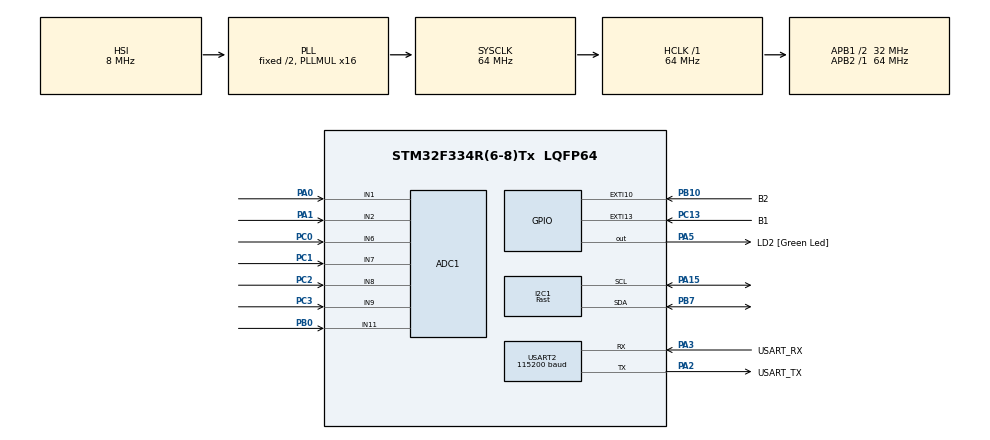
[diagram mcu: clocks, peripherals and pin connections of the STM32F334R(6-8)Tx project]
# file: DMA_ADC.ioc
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ADC1.Channel-0\#ChannelRegularConversion=ADC_CHANNEL_1
ADC1.Channel-1\#ChannelRegularConversion=ADC_CHANNEL_2
ADC1.Channel-2\#ChannelRegularConversion=ADC_CHANNEL_6
ADC1.Channel-3\#ChannelRegularConversion=ADC_CHANNEL_7
ADC1.Channel-4\#ChannelRegularConversion=ADC_CHANNEL_8
ADC1.Channel-5\#ChannelRegularConversion=ADC_CHANNEL_9
ADC1.Channel-6\#ChannelRegularConversion=ADC_CHANNEL_11
ADC1.ContinuousConvMode=ENABLE
ADC1.NbrOfConversion=7
ADC1.NbrOfConversionFlag=1
ADC1.Offset-0\#ChannelRegularConversion=0
ADC1.Offset-1\#ChannelRegularConversion=0
ADC1.Offset-2\#ChannelRegularConversion=0
ADC1.Offset-3\#ChannelRegularConversion=0
ADC1.Offset-4\#ChannelRegularConversion=0
ADC1.Offset-5\#ChannelRegularConversion=0
ADC1.Offset-6\#ChannelRegularConversion=0
ADC1.OffsetNumber-0\#ChannelRegularConversion=ADC_OFFSET_NONE
ADC1.OffsetNumber-1\#ChannelRegularConversion=ADC_OFFSET_NONE
ADC1.OffsetNumber-2\#ChannelRegularConversion=ADC_OFFSET_NONE
ADC1.OffsetNumber-3\#ChannelRegularConversion=ADC_OFFSET_NONE
ADC1.OffsetNumber-4\#ChannelRegularConversion=ADC_OFFSET_NONE
ADC1.OffsetNumber-5\#ChannelRegularConversion=ADC_OFFSET_NONE
ADC1.OffsetNumber-6\#ChannelRegularConversion=ADC_OFFSET_NONE
ADC1.Rank-0\#ChannelRegularConversion=1
ADC1.Rank-1\#ChannelRegularConversion=2
ADC1.Rank-2\#ChannelRegularConversion=3
ADC1.Rank-3\#ChannelRegularConversion=4
ADC1.Rank-4\#ChannelRegularConversion=5
ADC1.Rank-5\#ChannelRegularConversion=6
ADC1.Rank-6\#ChannelRegularConversion=7
ADC1.SamplingTime-0\#ChannelRegularConversion=ADC_SAMPLETIME_19CYCLES_5
ADC1.SamplingTime-1\#ChannelRegularConversion=ADC_SAMPLETIME_19CYCLES_5
ADC1.SamplingTime-2\#ChannelRegularConversion=ADC_SAMPLETIME_19CYCLES_5
ADC1.SamplingTime-3\#ChannelRegularConversion=ADC_SAMPLETIME_19CYCLES_5
ADC1.SamplingTime-4\#ChannelRegularConversion=ADC_SAMPLETIME_19CYCLES_5
ADC1.SamplingTime-5\#ChannelRegularConversion=ADC_SAMPLETIME_19CYCLES_5
ADC1.SamplingTime-6\#ChannelRegularConversion=ADC_SAMPLETIME_19CYCLES_5
ADC1.SamplingTimeOPAMP-6\#ChannelRegularConversion=ADC_SAMPLETIME_61CYCLES_5
ADC1.SubFamily=STM32F334x8
ADC1.master=1
Dma.ADC1.0.Direction=DMA_PERIPH_TO_MEMORY
Dma.ADC1.0.Instance=DMA1_Channel1
Dma.ADC1.0.MemDataAlignment=DMA_MDATAALIGN_WORD
Dma.ADC1.0.MemInc=DMA_MINC_ENABLE
Dma.ADC1.0.Mode=DMA_CIRCULAR
Dma.ADC1.0.PeriphDataAlignment=DMA_PDATAALIGN_WORD
Dma.ADC1.0.PeriphInc=DMA_PINC_DISABLE
Dma.ADC1.0.Priority=DMA_PRIORITY_LOW
Dma.Request0=ADC1
I2C1.I2C_Speed_Mode=I2C_Fast
I2C1.Timing=0x0000020B
Mcu.Family=STM32F3
Mcu.Name=STM32F334R(6-8)Tx
Mcu.Package=LQFP64
NVIC.DMA1_Channel1_IRQn=true\:0\:0\:false\:false\:true\:false\:true\:true
NVIC.EXTI15_10_IRQn=true\:0\:0\:false\:false\:true\:true\:true\:true
NVIC.PriorityGroup=NVIC_PRIORITYGROUP_0
NVIC.TIM2_IRQn=true\:0\:0\:false\:false\:true\:true\:true\:true
NVIC.TIM6_DAC1_IRQn=true\:0\:0\:false\:false\:true\:true\:true\:true
PA0.Mode=IN1-Single-Ended
PA0.Signal=ADC1_IN1
PA1.Mode=IN2-Single-Ended
PA1.Signal=ADC1_IN2
PA13.GPIO_Label=TMS
PA13.Mode=Serial_Wire
PA13.Signal=SYS_JTMS-SWDIO
PA14.GPIO_Label=TCK
PA14.Mode=Serial_Wire
PA14.Signal=SYS_JTCK-SWCLK
PA15.GPIO_Pu=GPIO_NOPULL
PA15.Mode=I2C
PA15.Signal=I2C1_SCL
PA2.GPIO_Label=USART_TX
PA2.Mode=Asynchronous
PA2.Signal=USART2_TX
PA3.GPIO_Label=USART_RX
PA3.Mode=Asynchronous
PA3.Signal=USART2_RX
PA5.GPIO_Label=LD2 [Green Led]
PA5.Signal=GPIO_Output
PB0.Mode=IN11-Single-Ended
PB0.Signal=ADC1_IN11
PB10.GPIO_Label=B2
PB10.GPIO_ModeDefaultEXTI=GPIO_MODE_IT_FALLING
PB10.Signal=GPXTI10
PB3.GPIO_Label=SWO
PB3.Signal=SYS_JTDO-TRACESWO
PB7.Mode=I2C
PB7.Signal=I2C1_SDA
PC0.Signal=ADCx_IN6
PC1.Signal=ADCx_IN7
PC13.GPIO_Label=B1
PC13.GPIO_ModeDefaultEXTI=GPIO_MODE_IT_FALLING
PC13.Signal=GPXTI13
PC14\ /\ OSC32_IN.Mode=LSE-External-Oscillator
PC14\ /\ OSC32_IN.Signal=RCC_OSC32_IN
PC15\ /\ OSC32_OUT.GPIO_Label=RCC_OSC32_OUT
PC15\ /\ OSC32_OUT.Mode=LSE-External-Oscillator
PC15\ /\ OSC32_OUT.Signal=RCC_OSC32_OUT
PC2.Signal=ADCx_IN8
PC3.Signal=ADCx_IN9
PF0\ /\ OSC_IN.Mode=HSE-External-Clock-Source
PF0\ /\ OSC_IN.Signal=RCC_OSC_IN
PF1\ /\ OSC_OUT.Signal=RCC_OSC_OUT
ProjectManager.HeapSize=0x200
ProjectManager.StackSize=0x400
ProjectManager.TargetToolchain=STM32CubeIDE
RCC.AHBFreq_Value=64000000
RCC.APB1CLKDivider=RCC_HCLK_DIV2
RCC.APB1Freq_Value=32000000
RCC.APB1TimFreq_Value=64000000
RCC.APB2Freq_Value=64000000
RCC.APB2TimFreq_Value=64000000
RCC.CortexFreq_Value=64000000
RCC.FLatency-AdvancedSettings=FLASH_LATENCY_2
RCC.HCLKFreq_Value=64000000
RCC.HSE_VALUE=8000000
RCC.HSI_VALUE=8000000
RCC.PLLMUL=RCC_PLL_MUL16
RCC.SYSCLKFreq_VALUE=64000000
RCC.SYSCLKSourceVirtual=RCC_SYSCLKSOURCE_PLLCLK
SH.ADCx_IN6.0=ADC1_IN6,IN6-Single-Ended
SH.ADCx_IN7.0=ADC1_IN7,IN7-Single-Ended
SH.ADCx_IN8.0=ADC1_IN8,IN8-Single-Ended
SH.ADCx_IN9.0=ADC1_IN9,IN9-Single-Ended
TIM2.Prescaler=72-1
TIM6.Period=10000
TIM6.Prescaler=7200-1
USART2.BaudRate=115200
USART2.VirtualMode-Asynchronous=VM_ASYNC
VP_TIM2_VS_ClockSourceINT.Mode=Internal
VP_TIM6_VS_ClockSourceINT.Mode=Enable_Timer
board=NUCLEO-F334R8

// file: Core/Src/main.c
/* USER CODE BEGIN Header */
/**
  ******************************************************************************
  * @file           : main.c
  * @brief          : Main program body
  ******************************************************************************
  * @attention
  *
  * Copyright (c) 2022 STMicroelectronics.
  * All rights reserved.
  *
  * This software is licensed under terms that can be found in the LICENSE file
  * in the root directory of this software component.
  * If no LICENSE file comes with this software, it is provided AS-IS.
  *
  ******************************************************************************
  */
/* USER CODE END Header */
#include "main.h"
#include "adc.h"
#include "dma.h"
#include "i2c.h"
#include "tim.h"
#include "usart.h"
#include "gpio.h"

/* USER CODE BEGIN Includes */
	#include "globalVars.h"
	#include "lcd_i2c.h"
/* USER CODE END Includes */

void SystemClock_Config(void);

int main(void)
{

  /* MCU Configuration--------------------------------------------------------*/

  /* Reset of all peripherals, Initializes the Flash interface and the Systick. */
  HAL_Init();

  /* Configure the system clock */
  SystemClock_Config();

  /* Initialize all configured peripherals */
  MX_GPIO_Init();
  MX_DMA_Init();
  MX_USART2_UART_Init();
  MX_ADC1_Init();
  MX_TIM2_Init();
  MX_TIM6_Init();
  MX_I2C1_Init();
  /* USER CODE BEGIN 2 */

	  HAL_TIM_Base_Start(&htim2); 	 // Start timer2 w trybie normalnym
	  HAL_TIM_Base_Start_IT(&htim6); // Start timera6 w trybie przerwania
	  disp.addr = (0x27 << 1);		 // Adres LCD'ka po I2C
	  disp.bl = true;				 // Włącz podświetlenie
	  lcd_init(&disp);				 // Inicjalizuj LCD

  /* USER CODE END 2 */

  /* Infinite loop */
  while (1)
  {

  }
}

void SystemClock_Config(void)
{
  RCC_OscInitTypeDef RCC_OscInitStruct = {0};
  RCC_ClkInitTypeDef RCC_ClkInitStruct = {0};
  RCC_PeriphCLKInitTypeDef PeriphClkInit = {0};

  /** Initializes the RCC Oscillators according to the specified parameters
  * in the RCC_OscInitTypeDef structure.
  */
  RCC_OscInitStruct.OscillatorType = RCC_OSCILLATORTYPE_HSI;
  RCC_OscInitStruct.HSIState = RCC_HSI_ON;
  RCC_OscInitStruct.HSICalibrationValue = RCC_HSICALIBRATION_DEFAULT;
  RCC_OscInitStruct.PLL.PLLState = RCC_PLL_ON;
  RCC_OscInitStruct.PLL.PLLSource = RCC_PLLSOURCE_HSI;
  RCC_OscInitStruct.PLL.PLLMUL = RCC_PLL_MUL16;
  if (HAL_RCC_OscConfig(&RCC_OscInitStruct) != HAL_OK)
  {
    Error_Handler();
  }

  /** Initializes the CPU, AHB and APB buses clocks
  */
  RCC_ClkInitStruct.ClockType = RCC_CLOCKTYPE_HCLK|RCC_CLOCKTYPE_SYSCLK
                              |RCC_CLOCKTYPE_PCLK1|RCC_CLOCKTYPE_PCLK2;
  RCC_ClkInitStruct.SYSCLKSource = RCC_SYSCLKSOURCE_PLLCLK;
  RCC_ClkInitStruct.AHBCLKDivider = RCC_SYSCLK_DIV1;
  RCC_ClkInitStruct.APB1CLKDivider = RCC_HCLK_DIV2;
  RCC_ClkInitStruct.APB2CLKDivider = RCC_HCLK_DIV1;

  if (HAL_RCC_ClockConfig(&RCC_ClkInitStruct, FLASH_LATENCY_2) != HAL_OK)
  {
    Error_Handler();
  }
  PeriphClkInit.PeriphClockSelection = RCC_PERIPHCLK_I2C1|RCC_PERIPHCLK_ADC12;
  PeriphClkInit.Adc12ClockSelection = RCC_ADC12PLLCLK_DIV1;
  PeriphClkInit.I2c1ClockSelection = RCC_I2C1CLKSOURCE_HSI;
  if (HAL_RCCEx_PeriphCLKConfig(&PeriphClkInit) != HAL_OK)
  {
    Error_Handler();
  }
}

void Error_Handler(void)
{
  __disable_irq();
  while (1)
  {
  }
}
